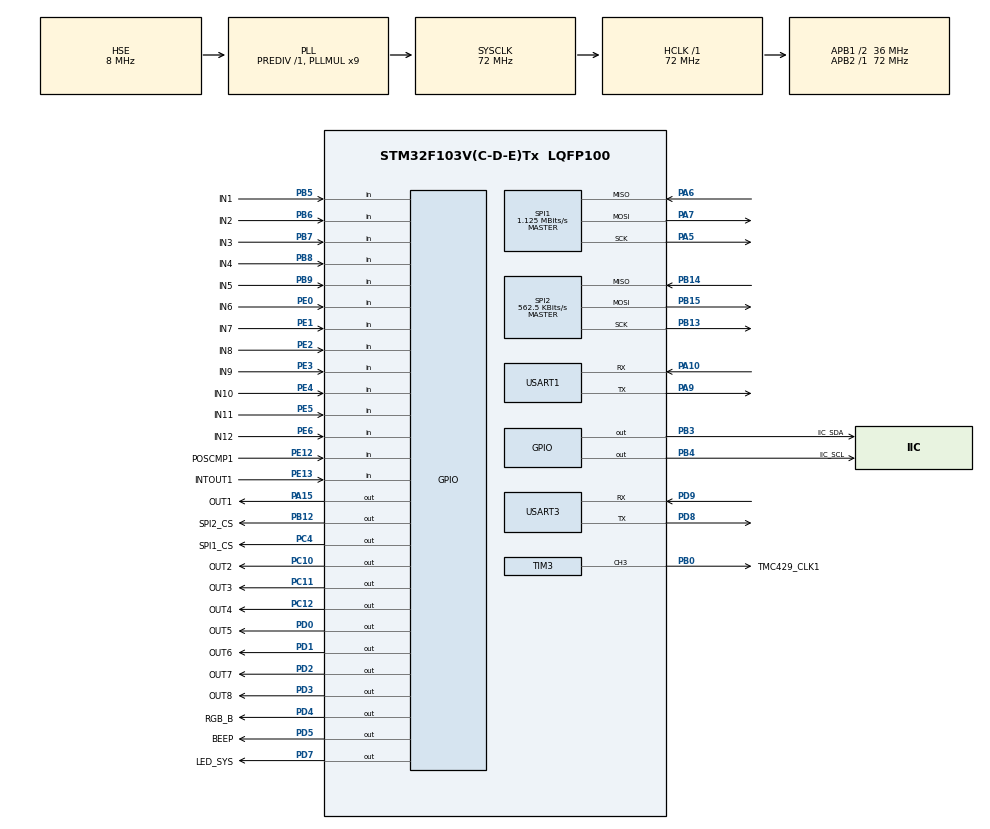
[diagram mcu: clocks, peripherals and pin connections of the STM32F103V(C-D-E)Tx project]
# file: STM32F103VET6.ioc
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Mcu.Family=STM32F1
Mcu.Name=STM32F103V(C-D-E)Tx
Mcu.Package=LQFP100
NVIC.PriorityGroup=NVIC_PRIORITYGROUP_4
NVIC.SPI2_IRQn=true\:4\:0\:true\:false\:true\:true\:true
NVIC.TIM1_UP_IRQn=true\:0\:0\:false\:false\:true\:true\:true
NVIC.USART1_IRQn=true\:5\:0\:true\:false\:true\:true\:true
NVIC.USART3_IRQn=true\:0\:0\:false\:false\:true\:true\:true
OSC_IN.Mode=HSE-External-Oscillator
OSC_IN.Signal=RCC_OSC_IN
OSC_OUT.Mode=HSE-External-Oscillator
OSC_OUT.Signal=RCC_OSC_OUT
PA10.Mode=Asynchronous
PA10.Signal=USART1_RX
PA13.Mode=Serial_Wire
PA13.Signal=SYS_JTMS-SWDIO
PA14.Mode=Serial_Wire
PA14.Signal=SYS_JTCK-SWCLK
PA15.GPIO_Label=OUT1
PA15.Signal=GPIO_Output
PA5.Mode=Full_Duplex_Master
PA5.Signal=SPI1_SCK
PA6.Mode=Full_Duplex_Master
PA6.Signal=SPI1_MISO
PA7.Mode=Full_Duplex_Master
PA7.Signal=SPI1_MOSI
PA9.Mode=Asynchronous
PA9.Signal=USART1_TX
PB0.GPIO_Label=TMC429_CLK1
PB0.GPIO_Speed=GPIO_SPEED_FREQ_HIGH
PB0.Signal=S_TIM3_CH3
PB12.GPIO_Label=SPI2_CS
PB12.Signal=GPIO_Output
PB13.Mode=Full_Duplex_Master
PB13.Signal=SPI2_SCK
PB14.Mode=Full_Duplex_Master
PB14.Signal=SPI2_MISO
PB15.Mode=Full_Duplex_Master
PB15.Signal=SPI2_MOSI
PB3.GPIO_Label=IIC_SDA
PB3.GPIO_ModeDefaultOutputPP=GPIO_MODE_OUTPUT_OD
PB3.PinState=GPIO_PIN_SET
PB3.Signal=GPIO_Output
PB4.GPIO_Label=IIC_SCL
PB4.GPIO_ModeDefaultOutputPP=GPIO_MODE_OUTPUT_OD
PB4.PinState=GPIO_PIN_SET
PB4.Signal=GPIO_Output
PB5.GPIO_Label=IN1
PB5.GPIO_PuPd=GPIO_PULLUP
PB5.Signal=GPIO_Input
PB6.GPIO_Label=IN2
PB6.GPIO_PuPd=GPIO_PULLUP
PB6.Signal=GPIO_Input
PB7.GPIO_Label=IN3
PB7.GPIO_PuPd=GPIO_PULLUP
PB7.Signal=GPIO_Input
PB8.GPIO_Label=IN4
PB8.GPIO_PuPd=GPIO_PULLUP
PB8.Signal=GPIO_Input
PB9.GPIO_Label=IN5
PB9.GPIO_PuPd=GPIO_PULLUP
PB9.Signal=GPIO_Input
PC10.GPIO_Label=OUT2
PC10.Signal=GPIO_Output
PC11.GPIO_Label=OUT3
PC11.Signal=GPIO_Output
PC12.GPIO_Label=OUT4
PC12.Signal=GPIO_Output
PC4.GPIO_Label=SPI1_CS
PC4.PinState=GPIO_PIN_SET
PC4.Signal=GPIO_Output
PD0.GPIO_Label=OUT5
PD0.Signal=GPIO_Output
PD1.GPIO_Label=OUT6
PD1.Signal=GPIO_Output
PD2.GPIO_Label=OUT7
PD2.Signal=GPIO_Output
PD3.GPIO_Label=OUT8
PD3.Signal=GPIO_Output
PD4.GPIO_Label=RGB_B
PD4.Signal=GPIO_Output
PD5.GPIO_Label=BEEP
PD5.Signal=GPIO_Output
PD7.GPIO_Label=LED_SYS
PD7.PinState=GPIO_PIN_SET
PD7.Signal=GPIO_Output
PD8.Mode=Asynchronous
PD8.Signal=USART3_TX
PD9.Mode=Asynchronous
PD9.Signal=USART3_RX
PE0.GPIO_Label=IN6
PE0.GPIO_PuPd=GPIO_PULLUP
PE0.Signal=GPIO_Input
PE1.GPIO_Label=IN7
PE1.GPIO_PuPd=GPIO_PULLUP
PE1.Signal=GPIO_Input
PE12.GPIO_Label=POSCMP1
PE12.GPIO_PuPd=GPIO_PULLUP
PE12.Signal=GPIO_Input
PE13.GPIO_Label=INTOUT1
PE13.GPIO_PuPd=GPIO_PULLUP
PE13.Signal=GPIO_Input
PE2.GPIO_Label=IN8
PE2.GPIO_PuPd=GPIO_PULLUP
PE2.Signal=GPIO_Input
PE3.GPIO_Label=IN9
PE3.GPIO_PuPd=GPIO_PULLUP
PE3.Signal=GPIO_Input
PE4.GPIO_Label=IN10
PE4.GPIO_PuPd=GPIO_PULLUP
PE4.Signal=GPIO_Input
PE5.GPIO_Label=IN11
PE5.GPIO_PuPd=GPIO_PULLUP
PE5.Signal=GPIO_Input
PE6.GPIO_Label=IN12
PE6.GPIO_PuPd=GPIO_PULLUP
PE6.Signal=GPIO_Input
ProjectManager.HeapSize=0x200
ProjectManager.StackSize=0x400
ProjectManager.TargetToolchain=MDK-ARM V5
RCC.AHBFreq_Value=72000000
RCC.APB1CLKDivider=RCC_HCLK_DIV2
RCC.APB1Freq_Value=36000000
RCC.APB1TimFreq_Value=72000000
RCC.APB2Freq_Value=72000000
RCC.APB2TimFreq_Value=72000000
RCC.HCLKFreq_Value=72000000
RCC.PLLMUL=RCC_PLL_MUL9
RCC.PLLSourceVirtual=RCC_PLLSOURCE_HSE
RCC.SYSCLKFreq_VALUE=72000000
RCC.SYSCLKSource=RCC_SYSCLKSOURCE_PLLCLK
RCC.USBFreq_Value=72000000
SH.S_TIM3_CH3.0=TIM3_CH3,PWM Generation3 CH3
SPI1.BaudRatePrescaler=SPI_BAUDRATEPRESCALER_64
SPI1.CLKPhase=SPI_PHASE_2EDGE
SPI1.CLKPolarity=SPI_POLARITY_HIGH
SPI1.CalculateBaudRate=1.125 MBits/s
SPI1.Direction=SPI_DIRECTION_2LINES
SPI1.Mode=SPI_MODE_MASTER
SPI1.VirtualType=VM_MASTER
SPI2.BaudRatePrescaler=SPI_BAUDRATEPRESCALER_64
SPI2.CLKPhase=SPI_PHASE_2EDGE
SPI2.CLKPolarity=SPI_POLARITY_HIGH
SPI2.CalculateBaudRate=562.5 KBits/s
SPI2.Direction=SPI_DIRECTION_2LINES
SPI2.Mode=SPI_MODE_MASTER
SPI2.VirtualType=VM_MASTER
TIM1.Period=7200
TIM1.Prescaler=100
TIM3.Channel-PWM\ Generation3\ CH3=TIM_CHANNEL_3
TIM3.OCFastMode_PWM-PWM\ Generation3\ CH3=TIM_OCFAST_ENABLE
TIM3.OCMode_PWM-PWM\ Generation3\ CH3=TIM_OCMODE_PWM2
TIM3.Period=5
TIM3.Pulse-PWM\ Generation3\ CH3=2
USART1.VirtualMode=VM_ASYNC
USART3.VirtualMode=VM_ASYNC
VP_TIM1_VS_ClockSourceINT.Mode=Internal
VP_TIM3_VS_ClockSourceINT.Mode=Internal
board=custom

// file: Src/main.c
/* USER CODE BEGIN Header */
/**
  ******************************************************************************
  * @file           : main.c
  * @brief          : Main program body
  ******************************************************************************
  * @attention
  *
  * <h2><center>&copy; Copyright (c) 2019 STMicroelectronics.
  * All rights reserved.</center></h2>
  *
  * This software component is licensed by ST under BSD 3-Clause license,
  * the "License"; You may not use this file except in compliance with the
  * License. You may obtain a copy of the License at:
  *                        opensource.org/licenses/BSD-3-Clause
  *
  ******************************************************************************
  */
/* USER CODE END Header */

#include "main.h"
#include "spi.h"
#include "tim.h"
#include "usart.h"
#include "gpio.h"

/* USER CODE BEGIN Includes */
//#include "bsp_include.h"
//#include "app_include.h"
//#include "app_Commands.h"
/* USER CODE END Includes */

/* USER CODE BEGIN PM */
#define TXBUFFERSIZE                      (COUNTOF(aTxBuffer) - 1)
/* Size of Reception buffer */
#define RXBUFFERSIZE                      TXBUFFERSIZE

/* Exported macro ------------------------------------------------------------*/
#define COUNTOF(__BUFFER__)   (sizeof(__BUFFER__) / sizeof(*(__BUFFER__)))
/* USER CODE END PM */

/* USER CODE BEGIN PV */
uint8_t aTxBuffer[] ="+0.001@\n";
/* USER CODE END PV */

void SystemClock_Config(void);

/* USER CODE BEGIN 0 */
//at24cxx_t at24c256=
//{
//	{0},
//	{PB_4,PB_3},	//SDA SCL
//	0xA0,
//};
/* USER CODE END 0 */
int main(void)
{
  /* USER CODE BEGIN 1 */
	uint32_t tickLedstart;
	uint32_t tickBeepstart;
  /* USER CODE END 1 */

  /* MCU Configuration--------------------------------------------------------*/

  /* Reset of all peripherals, Initializes the Flash interface and the Systick. */
  HAL_Init();

  /* Configure the system clock */
  SystemClock_Config();

  /* Initialize all configured peripherals */
  MX_GPIO_Init();
  MX_USART3_UART_Init();
  MX_SPI1_Init();
  MX_TIM3_Init();
  MX_TIM1_Init();
  MX_SPI2_Init();
  MX_USART1_UART_Init();
  /* USER CODE BEGIN 2 */
	//__HAL_UART_ENABLE_IT(&huart1, UART_IT_RXNE);

//	at24cxx_hw_init();
	HAL_Delay(50);

	tickLedstart=HAL_GetTick();
	tickBeepstart=HAL_GetTick();

  /* USER CODE END 2 */

  /* Infinite loop */
  while (1)
  {
		HAL_Delay(10);
		HAL_UART_Transmit(&huart3, (uint8_t*)aTxBuffer, TXBUFFERSIZE, 5000);
    /* USER CODE BEGIN 3 */
		//CommandCheckAndExe();
		if(abs((int)(HAL_GetTick()-tickLedstart))>350)
		{
			HAL_GPIO_TogglePin(LED_SYS_GPIO_Port,LED_SYS_Pin);
			tickLedstart=HAL_GetTick();
		}
//		if(abs((int)(HAL_GetTick()-tickBeepstart))>350)
//		{
//			if(beep_flash_on)
//			{
//				HAL_GPIO_TogglePin(BEEP_GPIO_Port,BEEP_Pin);
//				tickBeepstart=HAL_GetTick();
//			}
//			else
//			{
//				HAL_GPIO_WritePin(BEEP_GPIO_Port,BEEP_Pin, GPIO_PIN_RESET);
//			}
//		}
//		FlexButtonTest_APP();
  }

  /* USER CODE END 3 */
}

void SystemClock_Config(void)
{
  RCC_OscInitTypeDef RCC_OscInitStruct = {0};
  RCC_ClkInitTypeDef RCC_ClkInitStruct = {0};

  /** Initializes the CPU, AHB and APB busses clocks
  */
  RCC_OscInitStruct.OscillatorType = RCC_OSCILLATORTYPE_HSE;
  RCC_OscInitStruct.HSEState = RCC_HSE_ON;
  RCC_OscInitStruct.HSEPredivValue = RCC_HSE_PREDIV_DIV1;
  RCC_OscInitStruct.HSIState = RCC_HSI_ON;
  RCC_OscInitStruct.PLL.PLLState = RCC_PLL_ON;
  RCC_OscInitStruct.PLL.PLLSource = RCC_PLLSOURCE_HSE;
  RCC_OscInitStruct.PLL.PLLMUL = RCC_PLL_MUL9;
  if (HAL_RCC_OscConfig(&RCC_OscInitStruct) != HAL_OK)
  {
    Error_Handler();
  }
  /** Initializes the CPU, AHB and APB busses clocks
  */
  RCC_ClkInitStruct.ClockType = RCC_CLOCKTYPE_HCLK|RCC_CLOCKTYPE_SYSCLK
                              |RCC_CLOCKTYPE_PCLK1|RCC_CLOCKTYPE_PCLK2;
  RCC_ClkInitStruct.SYSCLKSource = RCC_SYSCLKSOURCE_PLLCLK;
  RCC_ClkInitStruct.AHBCLKDivider = RCC_SYSCLK_DIV1;
  RCC_ClkInitStruct.APB1CLKDivider = RCC_HCLK_DIV2;
  RCC_ClkInitStruct.APB2CLKDivider = RCC_HCLK_DIV1;

  if (HAL_RCC_ClockConfig(&RCC_ClkInitStruct, FLASH_LATENCY_2) != HAL_OK)
  {
    Error_Handler();
  }
}

void Error_Handler(void)
{
}

/************************ (C) COPYRIGHT STMicroelectronics *****END OF FILE****/
